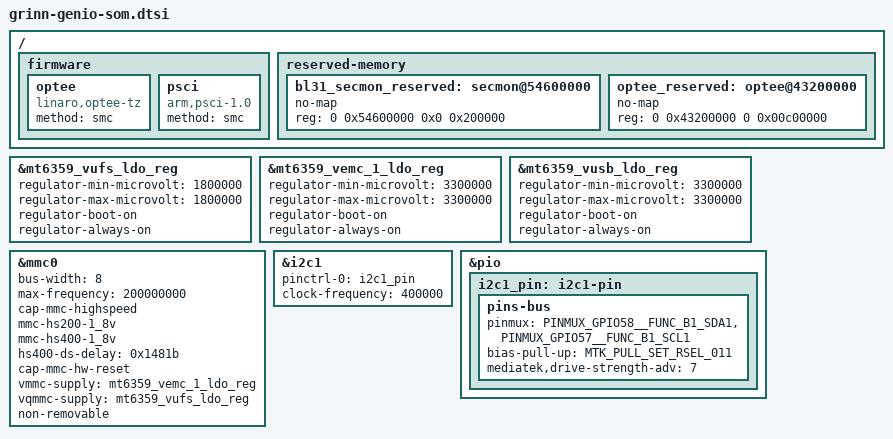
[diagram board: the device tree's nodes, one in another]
// SPDX-License-Identifier: GPL-2.0 OR MIT
/*
 * Copyright (C) 2025 Grinn sp. z o.o.
 * Author: Mateusz Koza <mateusz.koza@grinn-global.com>
 */

/ {
	firmware: firmware {
		optee {
			compatible = "linaro,optee-tz";
			method = "smc";
		};

		psci: psci {
			compatible = "arm,psci-1.0";
			method = "smc";
		};
	};

	reserved-memory {
		#address-cells = <2>;
		#size-cells = <2>;
		ranges;

		/* 2 MiB reserved for ARM Trusted Firmware (BL31) */
		bl31_secmon_reserved: secmon@54600000 {
			no-map;
			reg = <0 0x54600000 0x0 0x200000>;
		};

		/* 12 MiB reserved for OP-TEE (BL32)
		 * +-----------------------+ 0x43e0_0000
		 * |      SHMEM 2MiB       |
		 * +-----------------------+ 0x43c0_0000
		 * |        | TA_RAM  8MiB |
		 * + TZDRAM +--------------+ 0x4340_0000
		 * |        | TEE_RAM 2MiB |
		 * +-----------------------+ 0x4320_0000
		 */
		optee_reserved: optee@43200000 {
			no-map;
			reg = <0 0x43200000 0 0x00c00000>;
		};
	};
};

&mt6359_vufs_ldo_reg {
	regulator-min-microvolt = <1800000>;
	regulator-max-microvolt = <1800000>;
	regulator-boot-on;
	regulator-always-on;
};

&mt6359_vemc_1_ldo_reg {
	regulator-min-microvolt = <3300000>;
	regulator-max-microvolt = <3300000>;
	regulator-boot-on;
	regulator-always-on;
};

&mt6359_vusb_ldo_reg {
	regulator-min-microvolt = <3300000>;
	regulator-max-microvolt = <3300000>;
	regulator-boot-on;
	regulator-always-on;
};

&mmc0 {
	bus-width = <8>;
	max-frequency = <200000000>;
	cap-mmc-highspeed;
	mmc-hs200-1_8v;
	mmc-hs400-1_8v;
	hs400-ds-delay = <0x1481b>;
	cap-mmc-hw-reset;
	vmmc-supply = <&mt6359_vemc_1_ldo_reg>;
	vqmmc-supply = <&mt6359_vufs_ldo_reg>;
	non-removable;
	status = "okay";
};

&i2c1 {
	pinctrl-names = "default";
	pinctrl-0 = <&i2c1_pin>;
	clock-frequency = <400000>;
	status = "okay";
};

&pio {
	i2c1_pin: i2c1-pin {
		pins-bus {
			pinmux = <PINMUX_GPIO58__FUNC_B1_SDA1>,
				 <PINMUX_GPIO57__FUNC_B1_SCL1>;
			bias-pull-up = <MTK_PULL_SET_RSEL_011>;
			mediatek,drive-strength-adv = <7>;
		};
	};
};
